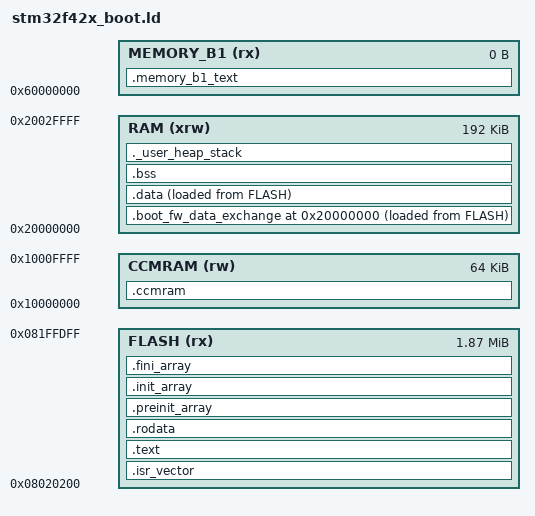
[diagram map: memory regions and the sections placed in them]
/*
******************************************************************************
File:     STM32F429VI_FLASH.ld
Info:     Generated by Atollic TrueSTUDIO(R) 9.3.0   2019-07-06

Abstract: Linker script for STM32F429VI device
          Set heap size, stack size, stack location, memory areas and
          sections according to application requirements.

The MIT License (MIT)
Copyright (c) 2019 STMicroelectronics

Permission is hereby granted, free of charge, to any person obtaining a copy
of this software and associated documentation files (the "Software"), to deal
in the Software without restriction, including without limitation the rights
to use, copy, modify, merge, publish, distribute, sublicense, and/or sell
copies of the Software, and to permit persons to whom the Software is
furnished to do so, subject to the following conditions:

The above copyright notice and this permission notice shall be included in all
copies or substantial portions of the Software.

THE SOFTWARE IS PROVIDED "AS IS", WITHOUT WARRANTY OF ANY KIND, EXPRESS OR
IMPLIED, INCLUDING BUT NOT LIMITED TO THE WARRANTIES OF MERCHANTABILITY,
FITNESS FOR A PARTICULAR PURPOSE AND NONINFRINGEMENT. IN NO EVENT SHALL THE
AUTHORS OR COPYRIGHT HOLDERS BE LIABLE FOR ANY CLAIM, DAMAGES OR OTHER
LIABILITY, WHETHER IN AN ACTION OF CONTRACT, TORT OR OTHERWISE, ARISING FROM,
OUT OF OR IN CONNECTION WITH THE SOFTWARE OR THE USE OR OTHER DEALINGS IN THE
SOFTWARE.

******************************************************************************
*/

/* Entry Point */
ENTRY(Reset_Handler)

/* Highest address of the user mode stack */
_estack = 0x20030000;    /* end of 128K RAM */

/* Generate a link error if heap and stack don't fit into RAM */
_Min_Heap_Size = 0x800;      /* required amount of heap  */
_Min_Stack_Size = 0x800; /* required amount of stack */

/* Specify the memory areas */
MEMORY
{
  FLASH (rx)      : ORIGIN = 0x08020200, LENGTH = 1919K
  RAM (xrw)       : ORIGIN = 0x20000000, LENGTH = 192K
  MEMORY_B1 (rx)  : ORIGIN = 0x60000000, LENGTH = 0K
  CCMRAM (rw)     : ORIGIN = 0x10000000, LENGTH = 64K
}

EXTERN (_scanf_float) /* Require proper _scanf_float rather than a stub */

/* Define output sections */
SECTIONS
{
  /* The startup code goes first into FLASH */
  .isr_vector :
  {
    . = ALIGN(4);
    KEEP(*(.isr_vector)) /* Startup code */
    . = ALIGN(4);
  } >FLASH

  /* The program code and other data goes into FLASH */
  .text :
  {
    . = ALIGN(4);
    *(.text)           /* .text sections (code) */
    *(.text*)          /* .text* sections (code) */
    *(.glue_7)         /* glue arm to thumb code */
    *(.glue_7t)        /* glue thumb to arm code */
    *(.eh_frame)

    KEEP (*(.init))
    KEEP (*(.fini))

    . = ALIGN(4);
    _etext = .;        /* define a global symbols at end of code */
  } >FLASH

  /* Constant data goes into FLASH */
  .rodata :
  {
    . = ALIGN(4);
    *(.rodata)         /* .rodata sections (constants, strings, etc.) */
    *(.rodata*)        /* .rodata* sections (constants, strings, etc.) */
    . = ALIGN(4);
  } >FLASH

  .preinit_array     :
  {
    PROVIDE_HIDDEN (__preinit_array_start = .);
    KEEP (*(.preinit_array*))
    PROVIDE_HIDDEN (__preinit_array_end = .);
  } >FLASH
  .init_array :
  {
    PROVIDE_HIDDEN (__init_array_start = .);
    KEEP (*(SORT(.init_array.*)))
    KEEP (*(.init_array*))
    PROVIDE_HIDDEN (__init_array_end = .);
  } >FLASH
  .fini_array :
  {
    PROVIDE_HIDDEN (__fini_array_start = .);
    KEEP (*(SORT(.fini_array.*)))
    KEEP (*(.fini_array*))
    PROVIDE_HIDDEN (__fini_array_end = .);
  } >FLASH

 /* to exchnage data between bootloader and application */
 /* this section is filled with zeros on each application start */
  .boot_fw_data_exchange 0x20000000 :
  {
  	_sboot_fw_data_exchange = .;  /* global symbol at start */
    KEEP (*(.boot_fw_data_exchange))
    . = ALIGN(4); /* allignment is important as 4 bytes are written to zero at once in startup code*/
    _eboot_fw_data_exchange = .;  /* global symbol at the end */
  } >RAM AT> FLASH /* AT> FLASH added to avoid the binary size increase*/

  /* used by the startup to initialize data */
  _sidata = LOADADDR(.data);

  /* Initialized data sections goes into RAM, load LMA copy after code */
  .data :
  {
    . = ALIGN(4);
    _sdata = .;        /* create a global symbol at data start */

    PROVIDE_HIDDEN (__start_log_components = .);
    KEEP(*(.data.log_components))
    PROVIDE_HIDDEN (__end_log_components = .);

    *(.data)           /* .data sections */
    *(.data*)          /* .data* sections */
    *(.RamFunc)        /* .RamFunc sections */
    *(.RamFunc*)       /* .RamFunc* sections */

    . = ALIGN(4);
    _edata = .;        /* define a global symbol at data end */
  } >RAM AT> FLASH

  _siccmram = LOADADDR(.ccmram);

  /* CCM-RAM section
  *
  * IMPORTANT NOTE!
  * If initialized variables will be placed in this section,
  * the startup code needs to be modified to copy the init-values.
  */
  .ccmram (NOLOAD) :
  {
    . = ALIGN(4);
    _sccmram = .;       /* create a global symbol at ccmram start */
    *(.ccmram_beginning)
    *(.ccmram)
    *(.ccmram*)

    . = ALIGN(4);
    _eccmram = .;       /* create a global symbol at ccmram end */
  } >CCMRAM

  /* Uninitialized data section */
  . = ALIGN(4);
  .bss :
  {
    /* This is used by the startup in order to initialize the .bss secion */
    _sbss = .;         /* define a global symbol at bss start */
    __bss_start__ = _sbss;
    *(.bss)
    *(.bss*)
    *(COMMON)

    . = ALIGN(4);
    _ebss = .;         /* define a global symbol at bss end */
    __bss_end__ = _ebss;
  } >RAM

  /* User_heap_stack section, used to check that there is enough RAM left */
  ._user_heap_stack :
  {
    . = ALIGN(4);
    PROVIDE ( end = . );
    PROVIDE ( _end = . );
    . = . + _Min_Heap_Size;
    . = . + _Min_Stack_Size;
    . = ALIGN(4);
  } >RAM

  /* MEMORY_bank1 section, code must be located here explicitly            */
  /* Example: extern int foo(void) __attribute__ ((section (".mb1text"))); */
  .memory_b1_text :
  {
    *(.mb1text)        /* .mb1text sections (code) */
    *(.mb1text*)       /* .mb1text* sections (code)  */
    *(.mb1rodata)      /* read-only data (constants) */
    *(.mb1rodata*)
  } >MEMORY_B1

  /* Remove information from the standard libraries */
  /DISCARD/ :
  {
    libc.a ( * )
    libm.a ( * )
    libgcc.a ( * )
    *(.ARM.exidx*)
    *(.ARM.extab* .gnu.linkonce.armextab.*)
  }

  .ARM.attributes 0 : { *(.ARM.attributes) }
}
